# ISD91000_v4_2 register map
File version: 1.0
Registers are 32-bit, read-write, reset 0x0 unless marked. A register's access mark holds for its fields unless they carry their own. Offsets are from the block's base; [hi:lo] are bit positions; {n}, {i} and the like mark numbered series; 'fields as' and 'values as' point back to an identical list.

## GPIO — GPIO Register Map
Base 0x50004000
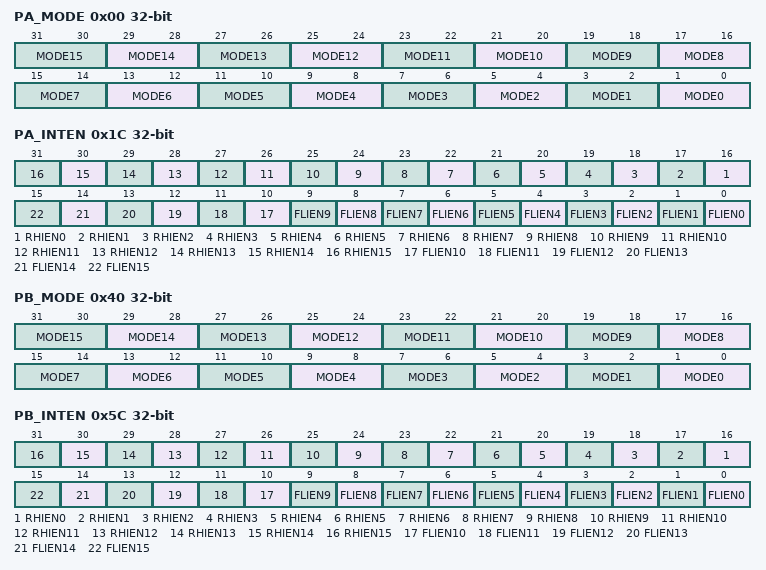
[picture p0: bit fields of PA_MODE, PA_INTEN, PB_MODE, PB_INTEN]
0x00 PA_MODE — GPIO PA Pin I/O Mode Control
  [all] fields
    0=GPIO Px[n] pin is in INPUT mode; 1=GPIO Px[n] pin is in OUTPUT mode; 2=GPIO Px[n] pin is in Open-Drain mode; 3=GPIO Px[n] pin is in Quasi-bidirectional mode
  [2n+1:2n] MODE{n} (n=0..15) — Port [A/B] Pin[N] I/O Mode Control. Each GPIO Px pin has four modes: Note: PB_MODE[15:6] are reserved to 0.
0x08 PA_DOUT reset 0xFFFF — GPIO PA Data Output Value
  [15:0] DOUT — Port [A/B] Pin[N] Output Value. Each of these bits controls the status of a GPIO pin when the GPIO pin is configured as output, open-drain or quasi-bidirectional mode. Note: PB_DOUT[15:6] are reserved to 0.
    0=GPIO port [A/B] Pin[n] will drive Low if the corresponding output mode bit is set; 1=GPIO port [A/B] Pin[n] will drive High if the corresponding output mode bit is set
0x10 PA_PIN ro (reset mask 0xFFFF0000) — GPIO PA Pin Value
  [15:0] PIN — Port [A/B] Pin[N] Pin Values. Each bit of the register reflects the actual status of the respective Px.n pin. If the bit is 1, it indicates the corresponding pin status is high; else the pin status is low. Note: PB_PIN[15:6] are reserved to 0.
0x18 PA_INTTYPE — GPIO PA Interrupt Trigger Type
  [15:0] TYPE — Port [A/B] Pin[N] Edge Or Level Detection Interrupt Trigger Type Control. TYPE[n] is used to control whether the interrupt mode is level triggered or edge triggered. If the interrupt mode is level triggered, the input source is sampled by one HCLK clock to generate the interrupt. Note: If level triggered interrupt is selected, then only one level can be selected in the Px_INTEN register. If both levels are set, the setting is ignored and no interrupt will occur
    0=Edge triggered interrupt; 1=Level triggered interrupt
0x1C PA_INTEN — GPIO PA Interrupt Enable
  [n+16] RHIEN{n} (n=0..15) — Port [A/B] Interrupt Enable By Input Rising Edge Or Input Level High. RHIEN[n] is used to enable the rising/high-level interrupt for each of the corresponding input Px.n pin. To set "1" also enables the pin wake-up function. When setting the RHIEN[n] (Px_INTEN[n+16]) bit to 1 : If the interrupt is configured as level trigger mode (TYPE[n] is set to 1), one interrupt will occur while the input Px.n state is at high level. If the interrupt is configured as edge trigger mode (TYPE[n] is set to 0), one interrupt will occur while he input Px.n state changes from low to high.
    0=Disable Px.n for low-to-high or level-high interrupt; 1=Enable Px.n for low-to-high or level-high interrupt
  [n] FLIEN{n} (n=0..15) — Port [A/B] Interrupt Enable By Input Falling Edge Or Input Level Low. FLIEN[n] is used to enable the falling/low-level interrupt for each of the corresponding input Px.n pin. To set "1" also enables the pin wake-up function. When setting the FLIEN[n] (Px_INTEN[n]) bit to 1 : If the interrupt is configured as level trigger mode (TYPE[n] is set to 1), one interrupt will occur while the input Px.n state is at low level. If the interrupt is configured as edge trigger mode (TYPE[n] is set to 0), one interrupt will occur while he input Px.n state changes from high to low.
    0=Disable Px.n for low-level or high-to-low interrupt; 1=Enable Px.n for low-level or high-to-low interrupt
0x20 PA_INTSRC — GPIO PA Interrupt Source Flag
  [15:0] INTSRC — Port [A/B] Interrupt Source Flag. Read operation:
    0=No interrupt from Px.n. No action; 1=Px.n generated an interrupt. Clear the corresponding pending interrupt
0x40 PB_MODE — GPIO PB Pin I/O Mode Control
  fields as PA_MODE
0x48 PB_DOUT reset 0xFFFF — GPIO PB Data Output Value
  fields as PA_DOUT
0x50 PB_PIN ro (reset mask 0xFFFF0000) — GPIO PB Pin Value
  fields as PA_PIN
0x58 PB_INTTYPE — GPIO PB Interrupt Trigger Type
  fields as PA_INTTYPE
0x5C PB_INTEN — GPIO PB Interrupt Enable
  fields as PA_INTEN
0x60 PB_INTSRC — GPIO PB Interrupt Source Flag
  fields as PA_INTSRC
{0x800+4i} PA{i}_PDIO (reset mask 0xFFFFFFF0) (i=0..15) — GPIO PA.n Pin Data Input/Output Register
  [0] PDIO — GPIO Px.n Pin Data Input/Output. Writing this bit can control one GPIO pin output value.
    0=Corresponding GPIO pin set to low; 1=Corresponding GPIO pin set to high
{0x840+4i} PB{i}_PDIO (reset mask 0xFFFFFFF0) (i=0..5) — GPIO PB.n Pin Data Input/Output Register
  fields as PA0_PDIO
